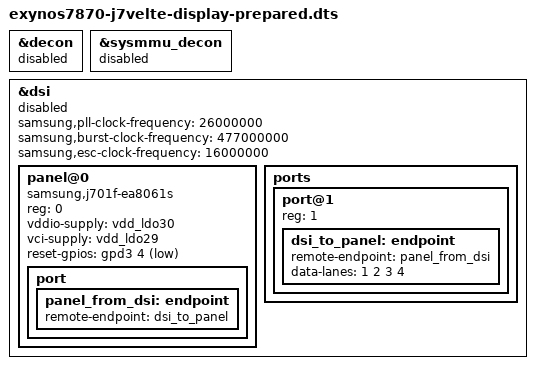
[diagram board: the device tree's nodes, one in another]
// SPDX-License-Identifier: GPL-2.0-only
/*
 * Codex 2026-10-10: OFFLINE display wiring candidate, not a display trial.
 * Includes the installed charger stage. Keep all three controllers disabled
 * until DMA/SysMMU and simpledrm takeover are resolved and a watched trial is
 * ready. The panel module separately requires allow_init=1.
 */
#include "exynos7870-j7velte-charger.dts"

&decon {
	status = "disabled";
};

&sysmmu_decon {
	status = "disabled";
};

&dsi {
	#address-cells = <1>;
	#size-cells = <0>;
	samsung,pll-clock-frequency = <26000000>;
	samsung,burst-clock-frequency = <477000000>;
	samsung,esc-clock-frequency = <16000000>;
	status = "disabled";

	panel@0 {
		compatible = "samsung,j701f-ea8061s";
		reg = <0>;
		vddio-supply = <&vdd_ldo30>;
		vci-supply = <&vdd_ldo29>;
		reset-gpios = <&gpd3 4 GPIO_ACTIVE_LOW>;

		port {
			panel_from_dsi: endpoint {
				remote-endpoint = <&dsi_to_panel>;
			};
		};
	};

	ports {
		port@1 {
			reg = <1>;
			dsi_to_panel: endpoint {
				remote-endpoint = <&panel_from_dsi>;
				data-lanes = <1 2 3 4>;
			};
		};
	};
};
